# PIC32MX350F256L register map
Vendor: Microchip
Registers are 32-bit, read-write, reset 0x0 unless marked. A register's access mark holds for its fields unless they carry their own. Addresses are absolute, and some are shared; only a register's first bit layout is shown; [hi:lo] are bit positions; {n}, {i} and the like mark numbered series.

## PORTD
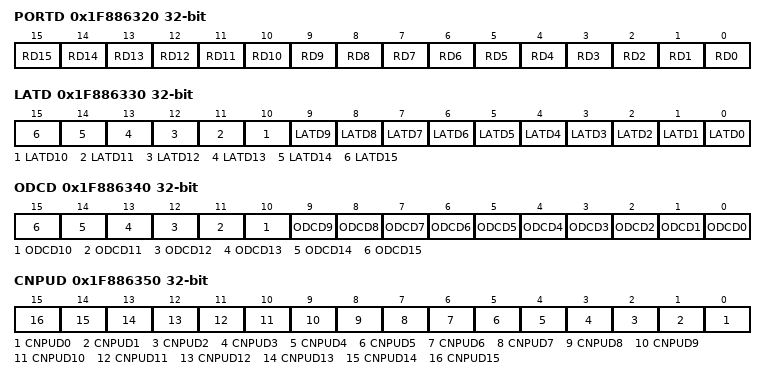
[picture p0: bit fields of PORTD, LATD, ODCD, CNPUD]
0x1F886320 PORTD reset not defined — (power-on value ----------------xxxxxxxxxxxxxxxx)
  [n] RD{n} (n=0..15)
0x1F886330 LATD reset not defined — (power-on value ----------------xxxxxxxxxxxxxxxx)
  [n] LATD{n} (n=0..15)
0x1F886340 ODCD
  [n] ODCD{n} (n=0..15)
0x1F886350 CNPUD reset not defined — (power-on value ----------------xxxxxxxxxxxxxxxx)
  [n] CNPUD{n} (n=0..15)
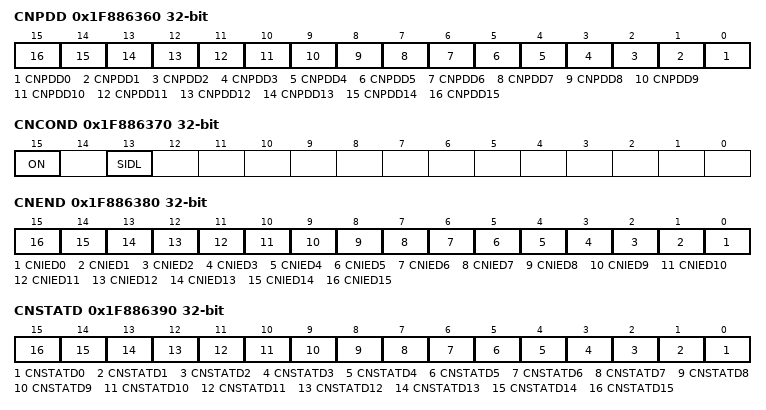
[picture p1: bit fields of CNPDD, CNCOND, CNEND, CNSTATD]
0x1F886360 CNPDD reset not defined — (power-on value ----------------xxxxxxxxxxxxxxxx)
  [n] CNPDD{n} (n=0..15)
0x1F886370 CNCOND
  [15] ON, [13] SIDL
0x1F886380 CNEND reset not defined — (power-on value 0000000000------xxxxxxxxxxxxxxxx)
  [n] CNIED{n} (n=0..15)
0x1F886390 CNSTATD reset not defined — (power-on value ----------------xxxxxxxxxxxxxxxx)
  [n] CNSTATD{n} (n=0..15)

## PORTE
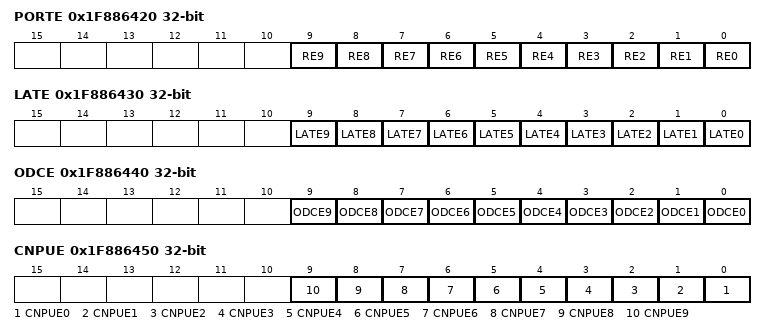
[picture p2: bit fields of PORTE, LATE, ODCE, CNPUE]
0x1F886420 PORTE reset not defined — (power-on value ----------------------xxxxxxxxxx)
  [n] RE{n} (n=0..9)
0x1F886430 LATE reset not defined — (power-on value ----------------------xxxxxxxxxx)
  [n] LATE{n} (n=0..9)
0x1F886440 ODCE
  [n] ODCE{n} (n=0..9)
0x1F886450 CNPUE reset not defined — (power-on value ----------------------xxxxxxxxxx)
  [n] CNPUE{n} (n=0..9)
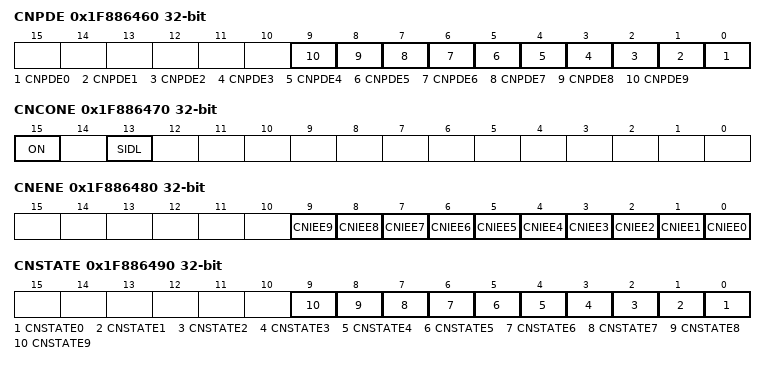
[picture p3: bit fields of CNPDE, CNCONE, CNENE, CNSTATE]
0x1F886460 CNPDE reset not defined — (power-on value ----------------------xxxxxxxxxx)
  [n] CNPDE{n} (n=0..9)
0x1F886470 CNCONE
  [15] ON, [13] SIDL
0x1F886480 CNENE reset not defined — (power-on value 0000000000------------xxxxxxxxxx)
  [n] CNIEE{n} (n=0..9)
0x1F886490 CNSTATE reset not defined — (power-on value ----------------------xxxxxxxxxx)
  [n] CNSTATE{n} (n=0..9)

## PORTF
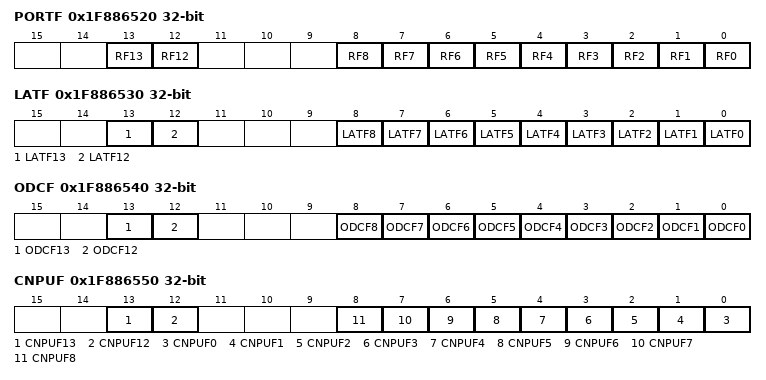
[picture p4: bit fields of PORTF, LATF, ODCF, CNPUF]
0x1F886520 PORTF reset not defined — (power-on value ------------------xx---xxxxxxxxx)
  [13] RF13, [12] RF12, [n] RF{n} (n=0..8)
0x1F886530 LATF reset not defined — (power-on value ------------------xx---xxxxxxxxx)
  [13] LATF13, [12] LATF12, [n] LATF{n} (n=0..8)
0x1F886540 ODCF
  [13] ODCF13, [12] ODCF12, [n] ODCF{n} (n=0..8)
0x1F886550 CNPUF reset not defined — (power-on value ------------------xx---xxxxxxxxx)
  [13] CNPUF13, [12] CNPUF12, [n] CNPUF{n} (n=0..8)
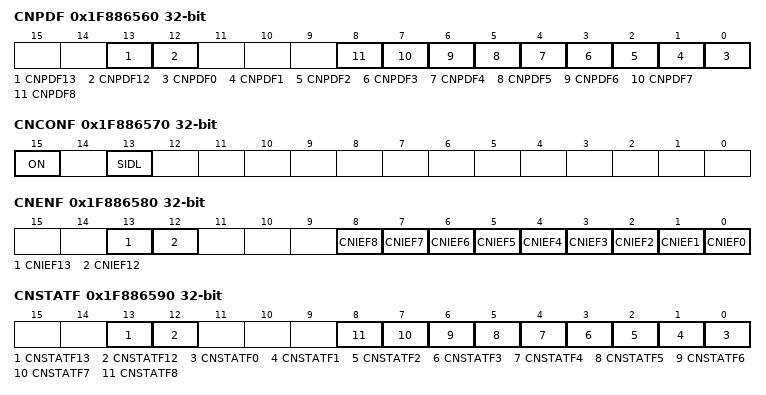
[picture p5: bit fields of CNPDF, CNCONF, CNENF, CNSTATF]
0x1F886560 CNPDF reset not defined — (power-on value ------------------xx---xxxxxxxxx)
  [13] CNPDF13, [12] CNPDF12, [n] CNPDF{n} (n=0..8)
0x1F886570 CNCONF
  [15] ON, [13] SIDL
0x1F886580 CNENF reset not defined — (power-on value 0000000000--------xx---xxxxxxxxx)
  [13] CNIEF13, [12] CNIEF12, [n] CNIEF{n} (n=0..8)
0x1F886590 CNSTATF reset not defined — (power-on value ------------------xx---xxxxxxxxx)
  [13] CNSTATF13, [12] CNSTATF12, [n] CNSTATF{n} (n=0..8)

## PORTG
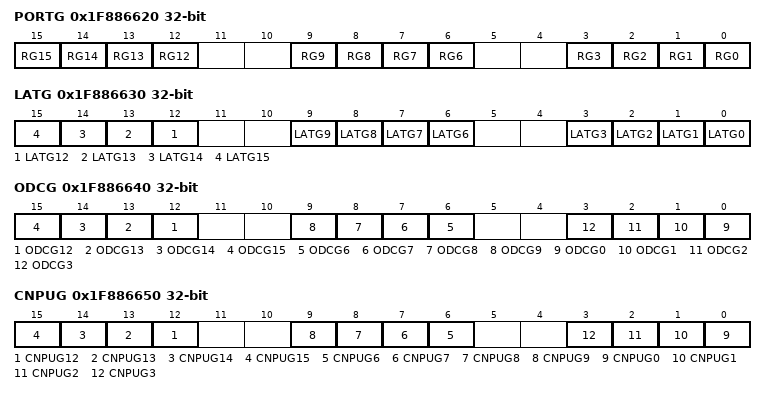
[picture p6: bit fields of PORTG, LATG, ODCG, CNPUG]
0x1F886620 PORTG reset not defined — (power-on value ----------------xxxx--xxxx--xxxx)
  [n] RG{n} (n=12..15), [n] RG{n} (n=6..9), [n] RG{n} (n=0..3)
0x1F886630 LATG reset not defined — (power-on value ----------------xxxx--xxxx--xxxx)
  [n] LATG{n} (n=12..15), [n] LATG{n} (n=6..9), [n] LATG{n} (n=0..3)
0x1F886640 ODCG
  [n] ODCG{n} (n=12..15), [n] ODCG{n} (n=6..9), [n] ODCG{n} (n=0..3)
0x1F886650 CNPUG reset not defined — (power-on value ----------------xxxx--xxxx--xxxx)
  [n] CNPUG{n} (n=12..15), [n] CNPUG{n} (n=6..9), [n] CNPUG{n} (n=0..3)
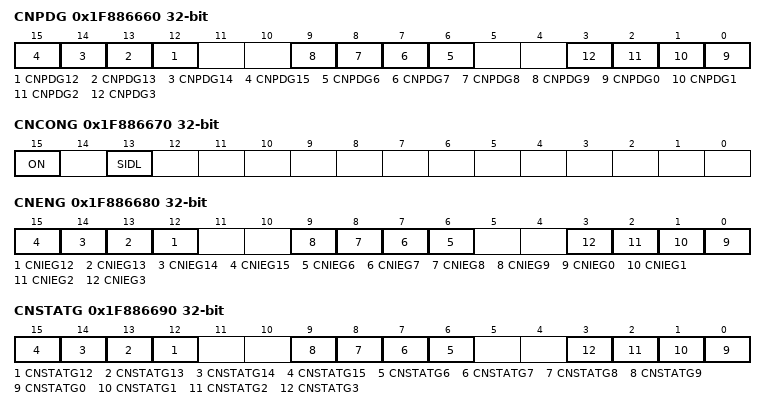
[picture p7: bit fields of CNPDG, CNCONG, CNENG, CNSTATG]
0x1F886660 CNPDG reset not defined — (power-on value ----------------xxxx--xxxx--xxxx)
  [n] CNPDG{n} (n=12..15), [n] CNPDG{n} (n=6..9), [n] CNPDG{n} (n=0..3)
0x1F886670 CNCONG
  [15] ON, [13] SIDL
0x1F886680 CNENG reset not defined — (power-on value 0000000000------xxxx--xxxx--xxxx)
  [n] CNIEG{n} (n=12..15), [n] CNIEG{n} (n=6..9), [n] CNIEG{n} (n=0..3)
0x1F886690 CNSTATG reset not defined — (power-on value ----------------xxxx--xxxx--xxxx)
  [n] CNSTATG{n} (n=12..15), [n] CNSTATG{n} (n=6..9), [n] CNSTATG{n} (n=0..3)

## OSC
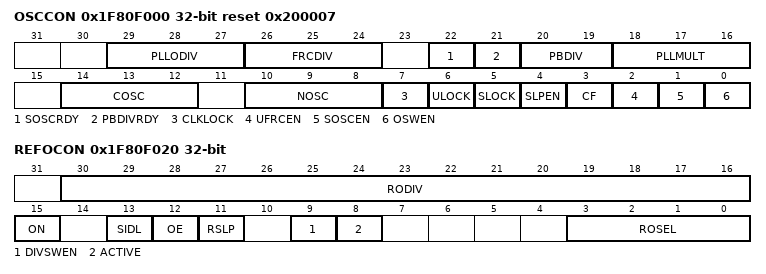
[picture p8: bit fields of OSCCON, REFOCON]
0x1F80F000 OSCCON reset 0x200007
  [29:27] PLLODIV, [26:24] FRCDIV, [22] SOSCRDY, [21] PBDIVRDY, [20:19] PBDIV, [18:16] PLLMULT, [14:12] COSC, [10:8] NOSC, [7] CLKLOCK, [6] ULOCK, [5] SLOCK, [4] SLPEN, [3] CF, [2] UFRCEN, [1] SOSCEN, [0] OSWEN
0x1F80F010 OSCTUN
  [5:0] TUN
0x1F80F020 REFOCON reset not defined — (power-on value -xxxxxxxxxxxxxxxxxxxxxxxx---xxxx)
  [30:16] RODIV, [15] ON, [13] SIDL, [12] OE, [11] RSLP, [9] DIVSWEN, [8] ACTIVE, [3:0] ROSEL
0x1F80F030 REFOTRIM reset not defined — (power-on value xxxxxxxxx-----------------------)
  [31:23] ROTRIM

## CFG
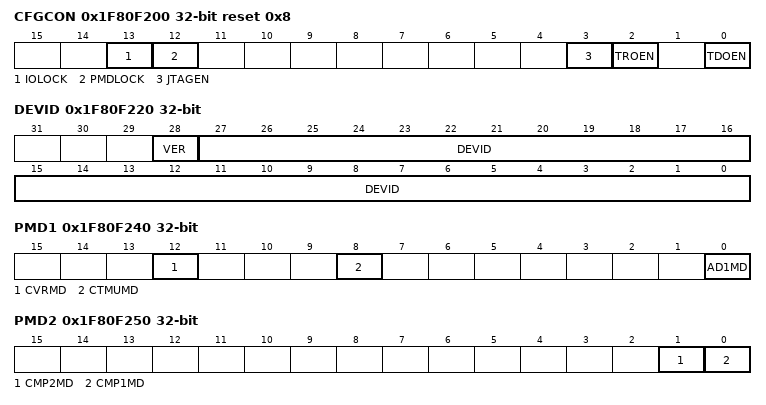
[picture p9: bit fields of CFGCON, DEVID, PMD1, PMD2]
0x1F80F200 CFGCON reset 0x8
  [13] IOLOCK, [12] PMDLOCK, [3] JTAGEN, [2] TROEN, [0] TDOEN
0x1F80F220 DEVID ro reset not defined — (power-on value xxxxxxxxxxxxxxxxxxxxxxxxxxxxxxxx)
  [28] VER, [27:0] DEVID
0x1F80F230 SYSKEY ro reset not defined — (power-on value xxxxxxxxxxxxxxxxxxxxxxxxxxxxxxxx)
0x1F80F240 PMD1
  [12] CVRMD, [8] CTMUMD, [0] AD1MD
0x1F80F250 PMD2
  [1] CMP2MD, [0] CMP1MD
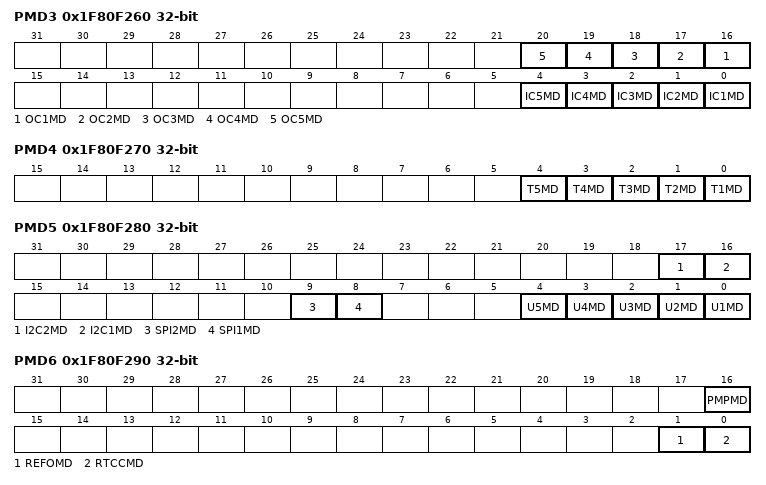
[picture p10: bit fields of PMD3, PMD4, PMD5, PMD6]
0x1F80F260 PMD3
  [n+15] OC{n}MD (n=1..5), [n-1] IC{n}MD (n=1..5)
0x1F80F270 PMD4
  [n-1] T{n}MD (n=1..5)
0x1F80F280 PMD5 reset not defined — (power-on value --------------00------00---xxx00)
  [17] I2C2MD, [16] I2C1MD, [9] SPI2MD, [8] SPI1MD, [n-1] U{n}MD (n=1..5)
0x1F80F290 PMD6
  [16] PMPMD, [1] REFOMD, [0] RTCCMD

## NVM
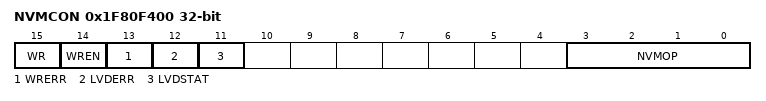
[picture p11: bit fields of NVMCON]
0x1F80F400 NVMCON
  [15] WR, [14] WREN, [13] WRERR, [12] LVDERR, [11] LVDSTAT, [3:0] NVMOP
0x1F80F410 NVMKEY wo
0x1F80F420 NVMADDR
0x1F80F430 NVMDATA
0x1F80F440 NVMSRCADDR

## RCON
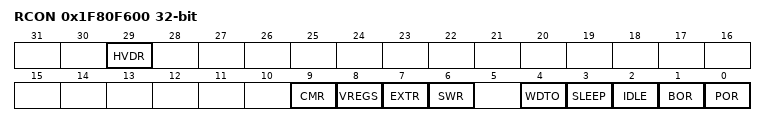
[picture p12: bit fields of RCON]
0x1F80F600 RCON reset not defined — (power-on value --x-------------------0000-00011)
  [29] HVDR, [9] CMR, [8] VREGS, [7] EXTR, [6] SWR, [4] WDTO, [3] SLEEP, [2] IDLE, [1] BOR, [0] POR
0x1F80F610 RSWRST
  [0] SWRST

## RPINRx
{0x1F80FA00+4i} INT{i}R (i=1..4)
  [3:0] INT{i}R
{0x1F80FA10+4i} T{i}CKR (i=2..5)
  [3:0] T{i}CKR
{0x1F80FA24+4i} IC{i}R (i=1..5)
  [3:0] IC{i}R
0x1F80FA48 OCFAR
  [3:0] OCFAR
{0x1F80FA48+8i} U{i}RXR (i=1..5)
  [3:0] U{i}RXR
{0x1F80FA4C+8i} U{i}CTSR (i=1..5)
  [3:0] U{i}CTSR
0x1F80FA84 SDI1R
  [3:0] SDI1R
0x1F80FA88 SS1R
  [3:0] SS1R
0x1F80FA90 SDI2R
  [3:0] SDI2R
0x1F80FA94 SS2R
  [3:0] SS2R
0x1F80FAD0 REFCLKIR
  [3:0] REFCLKIR

## RPORx
0x1F80FB38 RPA14R
  [3:0] RPA14R
0x1F80FB3C RPA15R
  [3:0] RPA15R
{0x1F80FB40+4i} RPB{i}R (i=0..3)
  [3:0] RPB{i}R
{0x1F80FB40+4i} RPB{i}R (i=5..10)
  [3:0] RPB{i}R
0x1F80FB78 RPB14R
  [3:0] RPB14R
0x1F80FB7C RPB15R
  [3:0] RPB15R
{0x1F80FB80+4i} RPC{i}R (i=1..4)
  [3:0] RPC{i}R
0x1F80FBB4 RPC13R
  [3:0] RPC13R
0x1F80FBB8 RPC14R
  [3:0] RPC14R
{0x1F80FBC0+4i} RPD{i}R (i=0..5)
  [3:0] RPD{i}R
{0x1F80FBC0+4i} RPD{i}R (i=8..12)
  [3:0] RPD{i}R
0x1F80FBF8 RPD14R
  [3:0] RPD14R
0x1F80FBFC RPD15R
  [3:0] RPD15R
0x1F80FC0C RPE3R
  [3:0] RPE3R
0x1F80FC14 RPE5R
  [3:0] RPE5R
0x1F80FC20 RPE8R
  [3:0] RPE8R
0x1F80FC24 RPE9R
  [3:0] RPE9R
{0x1F80FC40+4i} RPF{i}R (i=0..6)
  [3:0] RPF{i}R
0x1F80FC60 RPF8R
  [3:0] RPF8R
0x1F80FC70 RPF12R
  [3:0] RPF12R
0x1F80FC74 RPF13R
  [3:0] RPF13R
0x1F80FC80 RPG0R
  [3:0] RPG0R
0x1F80FC84 RPG1R
  [3:0] RPG1R
{0x1F80FC80+4i} RPG{i}R (i=6..9)
  [3:0] RPG{i}R
